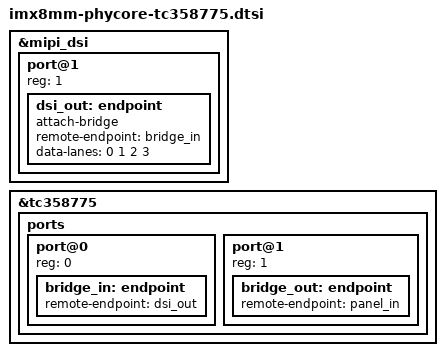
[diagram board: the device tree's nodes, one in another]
// SPDX-License-Identifier: GPL-2.0
/*
 * Copyright (C) 2022 PHYTEC Messtechnik GmbH
 * Author: Teresa Remmet <t.remmet@phytec.de>
 * Enables the Toshiba tc358775 bridge
 */

&mipi_dsi {
	status = "okay";

	#address-cells = <1>;
	#size-cells = <0>;

	port@1 {
		reg = <1>;

		dsi_out: endpoint {
			attach-bridge;
			remote-endpoint = <&bridge_in>;
			data-lanes = <0 1 2 3>;
		};
	};
};

&tc358775 {
	status = "okay";

	ports {
		#address-cells = <1>;
		#size-cells = <0>;

		port@0 {
			reg = <0>;

			bridge_in: endpoint {
				remote-endpoint = <&dsi_out>;
			};
		};

		port@1 {
			reg = <1>;

			bridge_out: endpoint {
				remote-endpoint = <&panel_in>;
			};
		};
	};
};
